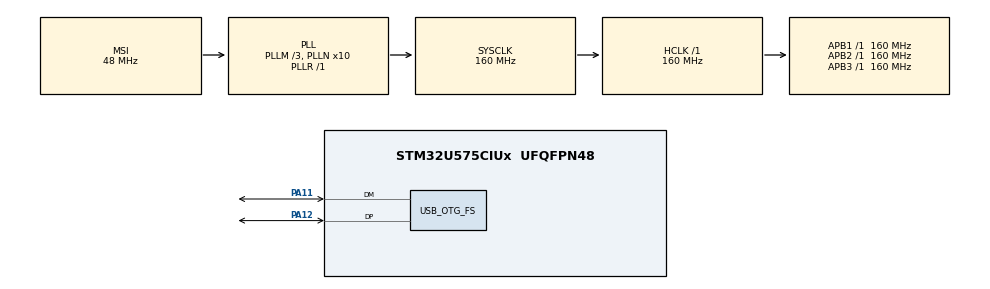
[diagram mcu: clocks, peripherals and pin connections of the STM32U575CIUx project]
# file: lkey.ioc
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CORTEX_M33_NS.userName=CORTEX_M33
FLASH.OB_User_Configuration_active=false
Mcu.Family=STM32U5
Mcu.Name=STM32U575CIUx
Mcu.Package=UFQFPN48
NVIC.OTG_FS_IRQn=true\:0\:0\:false\:false\:true\:true\:true\:true
NVIC.PriorityGroup=NVIC_PRIORITYGROUP_4
PA11.Mode=Device_Only
PA11.Signal=USB_OTG_FS_DM
PA12.Mode=Device_Only
PA12.Signal=USB_OTG_FS_DP
PH0-OSC_IN\ (PH0).Mode=HSE-External-Oscillator
PH0-OSC_IN\ (PH0).Signal=RCC_OSC_IN
PH1-OSC_OUT\ (PH1).Mode=HSE-External-Oscillator
PH1-OSC_OUT\ (PH1).Signal=RCC_OSC_OUT
ProjectManager.HeapSize=0x400
ProjectManager.StackSize=0x600
ProjectManager.TargetToolchain=CMake
RCC.ADCFreq_Value=16000000
RCC.AHBFreq_Value=160000000
RCC.APB1Freq_Value=160000000
RCC.APB1TimFreq_Value=160000000
RCC.APB2Freq_Value=160000000
RCC.APB2TimFreq_Value=160000000
RCC.APB3Freq_Value=160000000
RCC.CortexFreq_Value=160000000
RCC.EPOD_VALUE=48000000
RCC.HCLKFreq_Value=160000000
RCC.HSE_VALUE=16000000
RCC.HSI48_VALUE=48000000
RCC.HSI_VALUE=16000000
RCC.LSE_VALUE=32768
RCC.LSIDIV_VALUE=32000
RCC.MSIClockRange=RCC_MSIRANGE_0
RCC.MSI_VALUE=48000000
RCC.PLL1R=1
RCC.PLL2FRACN=0
RCC.PLL3FRACN=0
RCC.PLLFRACN=0
RCC.PLLM=3
RCC.PLLN=10
RCC.SYSCLKFreq_VALUE=160000000
RCC.SYSCLKSource=RCC_SYSCLKSOURCE_PLLCLK
RCC.USBFreq_Value=48000000
RCC.VCOOutputFreq_Value=160000000
USB_OTG_FS.VirtualMode=Device_Only
VP_CRC_VS_CRC.Mode=CRC_Activate
VP_FLASH_SIG_Activate_FlashIP.Mode=Activate_FlashIP
VP_HASH_VS_HASH.Mode=HASH_Activate
VP_ICACHE_VS_ICACHE.Mode=DefaultMode
VP_LPBAMQUEUE_VS_QUEUE.Mode=QUEUEMODE
VP_LPBAM_VS_SIG1.Mode=SmartRun
VP_LPBAM_VS_SIG4.Mode=LPDMA1
VP_MEMORYMAP_VS_MEMORYMAP.Mode=CurAppReg
VP_PWR_VS_SECSignals.Mode=Security/Privilege
VP_RNG_VS_RNG.Mode=RNG_Activate
VP_RTC_VS_RTC_Activate.Mode=RTC_Enabled
board=custom

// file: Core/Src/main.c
/* USER CODE BEGIN Header */
/**
  ******************************************************************************
  * @file           : main.c
  * @brief          : Main program body
  ******************************************************************************
  * @attention
  *
  * Copyright (c) 2025 STMicroelectronics.
  * All rights reserved.
  *
  * This software is licensed under terms that can be found in the LICENSE file
  * in the root directory of this software component.
  * If no LICENSE file comes with this software, it is provided AS-IS.
  *
  ******************************************************************************
  */
/* USER CODE END Header */
#include "main.h"

/* USER CODE BEGIN Includes */
#include <string.h>
#include "lkey.h"
#include "usb_descriptors.h"

/* USER CODE END Includes */

CRC_HandleTypeDef hcrc;

HASH_HandleTypeDef hhash;

RNG_HandleTypeDef hrng;

RTC_HandleTypeDef hrtc;

PCD_HandleTypeDef hpcd_USB_OTG_FS;

void SystemClock_Config(void);
static void MX_GPIO_Init(void);
static void MX_CRC_Init(void);
static void MX_HASH_Init(void);
static void MX_ICACHE_Init(void);
static void MX_RNG_Init(void);
static void MX_RTC_Init(void);
static void MX_USB_OTG_FS_PCD_Init(void);
static void MX_FLASH_Init(void);

/* USER CODE BEGIN 0 */

uint16_t tud_hid_get_report_cb(uint8_t itf, uint8_t report_id,
                               hid_report_type_t report_type,
                               uint8_t* buffer, uint16_t reqlen)
{
    // 空实现，直接返回请求长度
    return reqlen;
}

void tud_hid_set_report_cb(uint8_t itf, uint8_t report_id,
                           hid_report_type_t report_type,
                           uint8_t const* buffer, uint16_t bufsize)
{
}

/* USER CODE END 0 */

int main(void)
{

    /* MCU Configuration--------------------------------------------------------*/

    /* Reset of all peripherals, Initializes the Flash interface and the Systick. */
    HAL_Init();

    /* Configure the system clock */
    SystemClock_Config();

    /* Initialize all configured peripherals */
    MX_GPIO_Init();
    MX_CRC_Init();
    MX_HASH_Init();
    MX_ICACHE_Init();
    MX_RNG_Init();
    MX_RTC_Init();
    MX_USB_OTG_FS_PCD_Init();
    MX_FLASH_Init();
    /* USER CODE BEGIN 2 */
    tusb_init();
    LKEY_Crypto_Init(); /*
    const uint8_t* buffer = "ZeroForm";
    char pub[512];
    char priv[512];
    char pub_str[512];
    char priv_str[512];
    LKEY_ECC_GenerateKeyPair(pub,priv,MBEDTLS_ECP_DP_SECP256R1);
    LKEY_ECC_ExportKeyPair_PEM(pub_str,512,priv_str,512);*/
    /* USER CODE END 2 */

    /* Infinite loop */
    /* USER CODE BEGIN WHILE */
    while (1)
    {
        tud_task();
        /* USER CODE END WHILE */

    }
}

void SystemClock_Config(void)
{
    RCC_OscInitTypeDef RCC_OscInitStruct = {0};
    RCC_ClkInitTypeDef RCC_ClkInitStruct = {0};

    /** Configure the main internal regulator output voltage
    */
    if (HAL_PWREx_ControlVoltageScaling(PWR_REGULATOR_VOLTAGE_SCALE1) != HAL_OK)
    {
        Error_Handler();
    }

    /** Initializes the CPU, AHB and APB buses clocks
    */
    RCC_OscInitStruct.OscillatorType = RCC_OSCILLATORTYPE_HSI48 | RCC_OSCILLATORTYPE_LSI
        | RCC_OSCILLATORTYPE_MSI;
    RCC_OscInitStruct.HSI48State = RCC_HSI48_ON;
    RCC_OscInitStruct.LSIState = RCC_LSI_ON;
    RCC_OscInitStruct.MSIState = RCC_MSI_ON;
    RCC_OscInitStruct.MSICalibrationValue = RCC_MSICALIBRATION_DEFAULT;
    RCC_OscInitStruct.MSIClockRange = RCC_MSIRANGE_0;
    RCC_OscInitStruct.LSIDiv = RCC_LSI_DIV1;
    RCC_OscInitStruct.PLL.PLLState = RCC_PLL_ON;
    RCC_OscInitStruct.PLL.PLLSource = RCC_PLLSOURCE_MSI;
    RCC_OscInitStruct.PLL.PLLMBOOST = RCC_PLLMBOOST_DIV4;
    RCC_OscInitStruct.PLL.PLLM = 3;
    RCC_OscInitStruct.PLL.PLLN = 10;
    RCC_OscInitStruct.PLL.PLLP = 2;
    RCC_OscInitStruct.PLL.PLLQ = 2;
    RCC_OscInitStruct.PLL.PLLR = 1;
    RCC_OscInitStruct.PLL.PLLRGE = RCC_PLLVCIRANGE_1;
    RCC_OscInitStruct.PLL.PLLFRACN = 0;
    if (HAL_RCC_OscConfig(&RCC_OscInitStruct) != HAL_OK)
    {
        Error_Handler();
    }

    /** Initializes the CPU, AHB and APB buses clocks
    */
    RCC_ClkInitStruct.ClockType = RCC_CLOCKTYPE_HCLK | RCC_CLOCKTYPE_SYSCLK
        | RCC_CLOCKTYPE_PCLK1 | RCC_CLOCKTYPE_PCLK2
        | RCC_CLOCKTYPE_PCLK3;
    RCC_ClkInitStruct.SYSCLKSource = RCC_SYSCLKSOURCE_PLLCLK;
    RCC_ClkInitStruct.AHBCLKDivider = RCC_SYSCLK_DIV1;
    RCC_ClkInitStruct.APB1CLKDivider = RCC_HCLK_DIV1;
    RCC_ClkInitStruct.APB2CLKDivider = RCC_HCLK_DIV1;
    RCC_ClkInitStruct.APB3CLKDivider = RCC_HCLK_DIV1;

    if (HAL_RCC_ClockConfig(&RCC_ClkInitStruct, FLASH_LATENCY_4) != HAL_OK)
    {
        Error_Handler();
    }
}

static void MX_CRC_Init(void)
{

    hcrc.Instance = CRC;
    hcrc.Init.DefaultPolynomialUse = DEFAULT_POLYNOMIAL_ENABLE;
    hcrc.Init.DefaultInitValueUse = DEFAULT_INIT_VALUE_ENABLE;
    hcrc.Init.InputDataInversionMode = CRC_INPUTDATA_INVERSION_NONE;
    hcrc.Init.OutputDataInversionMode = CRC_OUTPUTDATA_INVERSION_DISABLE;
    hcrc.InputDataFormat = CRC_INPUTDATA_FORMAT_BYTES;
    if (HAL_CRC_Init(&hcrc) != HAL_OK)
    {
        Error_Handler();
    }
}

static void MX_FLASH_Init(void)
{

    if (HAL_FLASH_Unlock() != HAL_OK)
    {
        Error_Handler();
    }
    if (HAL_FLASH_Lock() != HAL_OK)
    {
        Error_Handler();
    }
}

static void MX_HASH_Init(void)
{

    hhash.Init.DataType = HASH_DATATYPE_32B;
    if (HAL_HASH_Init(&hhash) != HAL_OK)
    {
        Error_Handler();
    }
}

static void MX_ICACHE_Init(void)
{

    /** Enable instruction cache (default 2-ways set associative cache)
    */
    if (HAL_ICACHE_Enable() != HAL_OK)
    {
        Error_Handler();
    }
}

static void MX_RNG_Init(void)
{

    hrng.Instance = RNG;
    hrng.Init.ClockErrorDetection = RNG_CED_ENABLE;
    if (HAL_RNG_Init(&hrng) != HAL_OK)
    {
        Error_Handler();
    }
}

static void MX_RTC_Init(void)
{

    RTC_PrivilegeStateTypeDef privilegeState = {0};

    /** Initialize RTC Only
    */
    hrtc.Instance = RTC;
    hrtc.Init.HourFormat = RTC_HOURFORMAT_24;
    hrtc.Init.AsynchPrediv = 127;
    hrtc.Init.SynchPrediv = 255;
    hrtc.Init.OutPut = RTC_OUTPUT_DISABLE;
    hrtc.Init.OutPutRemap = RTC_OUTPUT_REMAP_NONE;
    hrtc.Init.OutPutPolarity = RTC_OUTPUT_POLARITY_HIGH;
    hrtc.Init.OutPutType = RTC_OUTPUT_TYPE_OPENDRAIN;
    hrtc.Init.OutPutPullUp = RTC_OUTPUT_PULLUP_NONE;
    hrtc.Init.BinMode = RTC_BINARY_NONE;
    if (HAL_RTC_Init(&hrtc) != HAL_OK)
    {
        Error_Handler();
    }
    privilegeState.rtcPrivilegeFull = RTC_PRIVILEGE_FULL_NO;
    privilegeState.backupRegisterPrivZone = RTC_PRIVILEGE_BKUP_ZONE_NONE;
    privilegeState.backupRegisterStartZone2 = RTC_BKP_DR0;
    privilegeState.backupRegisterStartZone3 = RTC_BKP_DR0;
    if (HAL_RTCEx_PrivilegeModeSet(&hrtc, &privilegeState) != HAL_OK)
    {
        Error_Handler();
    }
}

static void MX_USB_OTG_FS_PCD_Init(void)
{

    hpcd_USB_OTG_FS.Instance = USB_OTG_FS;
    hpcd_USB_OTG_FS.Init.dev_endpoints = 6;
    hpcd_USB_OTG_FS.Init.speed = PCD_SPEED_FULL;
    hpcd_USB_OTG_FS.Init.phy_itface = PCD_PHY_EMBEDDED;
    hpcd_USB_OTG_FS.Init.Sof_enable = DISABLE;
    hpcd_USB_OTG_FS.Init.low_power_enable = DISABLE;
    hpcd_USB_OTG_FS.Init.lpm_enable = DISABLE;
    hpcd_USB_OTG_FS.Init.battery_charging_enable = DISABLE;
    hpcd_USB_OTG_FS.Init.use_dedicated_ep1 = DISABLE;
    hpcd_USB_OTG_FS.Init.vbus_sensing_enable = DISABLE;
    hpcd_USB_OTG_FS.Init.dma_enable = DISABLE;
    if (HAL_PCD_Init(&hpcd_USB_OTG_FS) != HAL_OK)
    {
        Error_Handler();
    }
}

static void MX_GPIO_Init(void)
{

    /* GPIO Ports Clock Enable */
    __HAL_RCC_GPIOH_CLK_ENABLE();
    __HAL_RCC_GPIOA_CLK_ENABLE();

}

void Error_Handler(void)
{
    __disable_irq();
    while (1)
    {
    }
}
